# ADuCM410 register map
Vendor: Analog Devices; Series: ADuCM410; File version: 1p0
CPU: CM33 r0p1, little endian, MPU, FPU, 3 interrupt priority bits
Registers are 32-bit, read-write, reset 0x0 unless marked. A register's access mark holds for its fields unless they carry their own. Offsets are from the block's base; [hi:lo] are bit positions; {n}, {i} and the like mark numbered series.

## UART0
Base 0x40020000
Same registers: UART1 0x40020400
0x00 RX — Receive/transfer Buffer Register
  [7:0] RBR ro — Receive Buffer Register
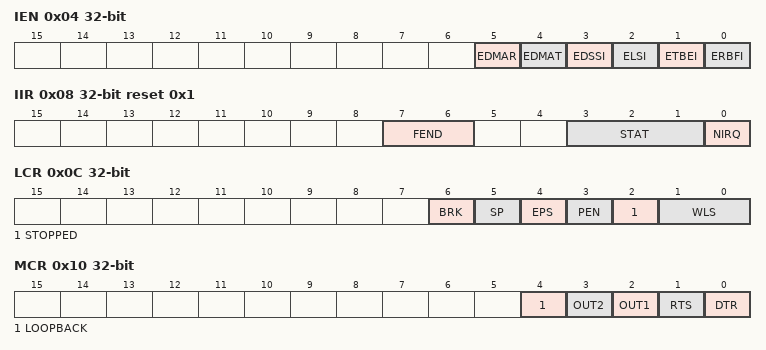
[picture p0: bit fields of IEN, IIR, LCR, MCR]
0x04 IEN — Interrupt Enable
  [5] EDMAR — DMA Requests in Receive Mode
    0=DIS (DMA Requests Disabled); 1=EN (DMA Requests Enabled)
  [4] EDMAT — DMA Requests in Transmit Mode
    0=DIS (DMA Requests are Disabled); 1=EN (DMA Requests are Enabled)
  [3] EDSSI — Modem Status Interrupt
    0=DIS (Interrupt Disabled); 1=EN (Interrupt Enabled)
  [2] ELSI — Rx Status Interrupt
    0=DIS (Interrupt Disabled); 1=EN (Interrupt Enabled)
  [1] ETBEI — Transmit Buffer Empty Interrupt
    0=DIS (Interrupt Disabled); 1=EN (Interrupt Enabled)
  [0] ERBFI — Receive Buffer Full Interrupt
    0=DIS (Interrupt Disabled); 1=EN (Interrupt Enabled)
0x08 IIR reset 0x1 — Interrupt ID
  [7:6] FEND ro — FIFO Enabled
    0=DIS (FIFO Not Enabled, 16450 Mode); 3=EN (FIFO Enabled, 16550 Mode)
  [3:1] STAT ro — Interrupt Status
    0=MODEMINT (Modem Status Interrupt (Read MSR Register to Clear)); 1=TXEMPTYINT (Transmit Buffer Empty Interrupt (Write to Tx Register or Read IIR Register to Clear)); 2=RXFULLINT (Receive Buffer Full Interrupt (Read Rx Register to Clear)); 3=RXLINEINT (Receive Line Status Interrupt (Read LSR Register to Clear)); 6=RXTIMEOUTINT (Receive FIFO Time-out Interrupt (Read Rx Register to Clear))
  [0] NIRQ ro — Interrupt Flag
0x0C LCR — Line Control
  [6] BRK range 0x00000000..0x00000001 — Set Break
  [5] SP — Stick Parity
    0=STICK (Parity Will Not Be Forced Based on Parity Select and Parity Enable Bits.); 1=EPSPEN (Parity Forced Based on Parity Select and Parity Enable Bits.)
  [4] EPS — Parity Select
    0=ODD (Odd Parity Will Be Transmitted and Checked.); 1=EVEN (Even Parity Will Be Transmitted and Checked.)
  [3] PEN — Parity Enable
    0=DIS (Parity Will Not Be Transmitted or Checked.); 1=EN (Parity Will Be Transmitted and Checked.)
  [2] STOPPED — Stop Bit
    0=ONTBIT (Send 1 Stop Bit Regardless of the Word Length Select Bit); 1=MULTIBIT (Send a Number of Stop Bits Based on the Word Length as Follows: WLS = 00, 1.5 Stop Bits Transmitted (5-bit Word Length) WLS = 01 or 10 or 11, 2 Stop Bits Transmitted (6 or 7 or 8-bit Word Length))
  [1:0] WLS — Word Length Select
    {v}=BITS{v+5} ({v+5} Bits) (v=0..3)
0x10 MCR — Modem Control
  [4] LOOPBACK — Loop Back Mode
    0=DIS (Normal Operation - Loopback Disabled); 1=EN (Loopback Enabled)
  [3] OUT2 — Output 2
    0=FORCE1 (Force NOUT2 to a Logic 1); 1=FORCE0 (Force NOUT2 to a Logic 0)
  [2] OUT1 — Output 1
    0=FORCE1 (Force NOUT1 to a Logic 1); 1=FORCE0 (Force NOUT1 to a Logic 0)
  [1] RTS — Request to Send
    0=FORCE1 (Force NRTS to a Logic 1); 1=FORCE0 (Force NRTS to a Logic 0)
  [0] DTR — Data Terminal Ready
    0=FORCE1 (Force NDTR to a Logic 1); 1=FORCE0 (Force NDTR to a Logic 0)
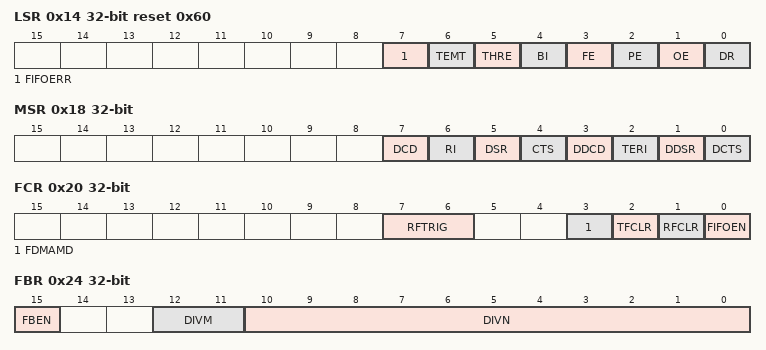
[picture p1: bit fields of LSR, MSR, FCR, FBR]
0x14 LSR reset 0x60 — Line Status
  [7] FIFOERR ro — FIFO Error
  [6] TEMT ro — Transmit and Shift Register Empty Status
    0=NOTEMPTY (Tx Register Has Been Written to and Contains Data to Be Transmitted. Care Should Be Taken Not to Overwrite Its Value.); 1=EMPTY (Tx Register and the Transmit Shift Register are Empty and It is Safe to Write New Data to the Tx Register. Data Has Been Transmitted.)
  [5] THRE ro — Transmit Register Empty
    0=NOTEMPTY (Tx Register Has Been Written to and Contains Data to Be Transmitted. Care Should Be Taken Not to Overwrite Its Value.); 1=EMPTY (Tx Register is Empty and It is Safe to Write New Data to Tx Register the Previous Data May Not Have Been Transmitted Yet and Can Still Be Present in the Shift Register.)
  [4] BI ro — Break Indicator
  [3] FE ro — Framing Error
    0=OKAY (No Invalid Stop Bit Was Detected.); 1=INVALIDSTOP (An Invalid Stop Bit Was Detected on a Received Word.)
  [2] PE ro — Parity Error
    0=NOERR (No Parity Error Was Detected.); 1=ERRORS (A Parity Error Occurred on a Received Word.)
  [1] OE ro — Overrun Error
    0=OKAY (Receive Data Has Not Been Overwritten.); 1=OVERWRITTEN (Receive Data Was Overwritten by New Data Before Rx Register Was Read.)
  [0] DR ro — Data Ready
    0=NOTREADY (Rx Register Does Not Contain New Receive Data.); 1=READY (Rx Register Contains Receive Data That Should Be Read.)
0x18 MSR — Modem Status
  [7] DCD ro — Data Carrier Detect
    0=HIGH (NDCD is Currently Logic High.); 1=LOW (NDCD is Currently Logic Low.)
  [6] RI ro — Ring Indicator
    0=HIGH (NRI is Currently Logic High.); 1=LOW (NRI is Currently Logic Low.)
  [5] DSR ro — Data Set Ready
    0=HIGH (NDSR is Currently Logic High); 1=LOW (NDSR is Currently Logic Low)
  [4] CTS ro — Clear to Send
    0=HIGH (NCTS is Currently Logic High); 1=LOW (NCTS is Currently Logic Low)
  [3] DDCD ro — Delta DCD
    0=NOCHANGE (Data Carrier Detect Bit Has Not Changed State Since MSR Register Was Last Read); 1=CHANGED (Data Carrier Detect Bit Changed State Since MSR Register Last Read)
  [2] TERI ro — Trailing Edge RI
    0=NOTCHANGED (Ring Indicator Bit Has Not Changed from 0 to 1 Since MSR Register Last Read); 1=CHANGED (Ring Indicator Bit Changed from 0 to 1 Since MSR Register Last Read)
  [1] DDSR ro — Delta DSR
    0=NOCHANGE (Data Set Ready Bit Has Not Changed State Since MSR Register Was Last Read); 1=CHANGED (Data Set Ready Bit Changed State Since MSR Register Last Read)
  [0] DCTS ro — Delta CTS
    0=NOCHANGE (Clear to Send Bit Has Not Changed State Since MSR Register Was Last Read); 1=CHANGED (Clear to Send Bit Changed State Since MSR Register Last Read)
0x1C SCR — Scratch Buffer
  [7:0] SCR range 0x00000000..0x000000FF — Scratch
0x20 FCR — FIFO Control
  [7:6] RFTRIG — RX FIFO Trig Level
    0=BYTE1 (1 Byte to Trig RX Interrupt); 1=BYTE4 (4 Byte to Trig RX Interrupt); 2=BYTE8 (8 Byte to Trig RX Interrupt); 3=BYTE14 (14 Byte to Trig RX Interrupt)
  [3] FDMAMD — FIFO DMA Mode
    0=MODE0 (In DMA Mode 0, RX DMA Request Will Be Asserted Whenever There's Data in RBR or RX FIFO and De-assert Whenever RBR or RX FIFO is Empty; TX DMA Request Will Be Asserted Whenever THR or TX FIFO is Empty and De-assert Whenever Data Written To.); 1=MODE1 (In DMA Mode 1, RX DMA Request Will Be Asserted Whenever RX FIFO Trig Level or Time Out Reached and De-assert Thereafter When RX FIFO is Empty; TX DMA Request Will Be Asserted Whenever TX FIFO is Empty and De-assert Thereafter When TX FIFO is Completely Filled up Full.)
  [2] TFCLR wo range 0x00000000..0x00000001 — Clear TX FIFO
  [1] RFCLR wo range 0x00000000..0x00000001 — Clear RX FIFO
  [0] FIFOEN range 0x00000000..0x00000001 — FIFO Enable as to Work in 16550 Mode
0x24 FBR — Fractional Baud Rate
  [15] FBEN range 0x00000000..0x00000001 — Fractional Baud Rate Generator Enable
  [12:11] DIVM range 0x00000000..0x00000003 — Fractional Baud Rate M Divide Bits 1 to 3
  [10:0] DIVN range 0x00000000..0x000007FF — Fractional Baud Rate N Divide Bits 0 to 2047
0x28 DIV — Baudrate Divider
  [15:0] DIV range 0x00000000..0x0000FFFF — Baud Rate Divider
0x2C LCR2 reset 0x2 — Second Line Control
  [1:0] OSR — Over Sample Rate
    0=Over Sample by 4; 1=Over Sample by 8; 2=Over Sample by 16; 3=Over Sample by 32
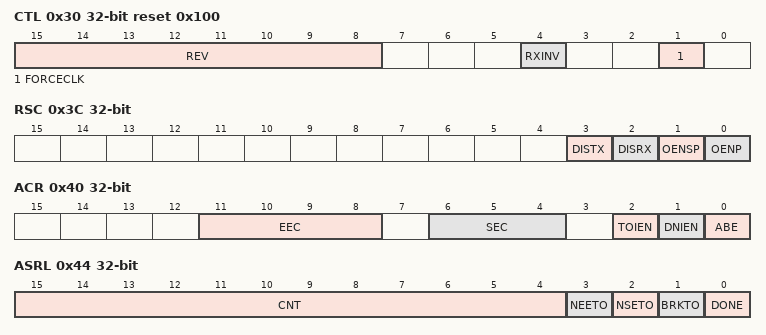
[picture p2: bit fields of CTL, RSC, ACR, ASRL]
0x30 CTL reset 0x100 — UART Control Register
  [15:8] REV ro — UART Revision ID
  [4] RXINV — Invert Receiver Line
    0=EN000 (Don't Invert Receiver Line (idling High)); 1=EN001 (Invert Receiver Line (idling Low))
  [1] FORCECLK — Force UCLK on
    0=GATEUCLK (UCLK Automatically Gated); 1=UCLKEN (UCLK Always Working)
0x34 RFC — RX FIFO Byte Count
  [4:0] RFC ro — Current RX FIFO Data Bytes
0x38 TFC — TX FIFO Byte Count
  [4:0] TFC ro — Current TX FIFO Data Bytes
0x3C RSC — RS485 Half-duplex Control
  [3] DISTX range 0x00000000..0x00000001 — Hold off TX When Receiving
  [2] DISRX range 0x00000000..0x00000001 — Disable RX When Transmitting
  [1] OENSP — SOUT_EN De-assert Before Full Stop Bit(s)
    0=FULLBIT (SOUT_EN De-assert Same Time as Full Stop Bit(s)); 1=HALFBIT (SOUT_EN De-assert Half-bit Earlier Than Full Stop Bit(s))
  [0] OENP — SOUT_EN Polarity
    0=HIGHACTIVE; 1=LOWACTIVE
0x40 ACR — Auto Baud Control
  [11:8] EEC — Ending Edge Count
    0=FIRST (First Edge); 1=SECOND (Second Edge); 2=THIRD (Third Edge); 3=FOURTH (Fourth Edge); 4=FIFTH (Fifth Edge); 5=SIXTH (Sixth Edge); 6=SEVENTH (Seventh Edge); 7=EIGHTH (Eighth Edge); 8=NINTH (Ninth Edge)
  [6:4] SEC — Starting Edge Count
    0=FIRST (First Edge (always the Falling Edge of START Bit)); 1=SECOND (Second Edge); 2=THIRD (Third Edge); 3=FOURTH (Fourth Edge); 4=FIFTH (Fifth Edge); 5=SIXTH (Sixth Edge); 6=SEVENTH (Seventh Edge); 7=EIGHTH (Eighth Edge)
  [2] TOIEN range 0x00000000..0x00000001 — Enable Time-out Interrupt
  [1] DNIEN range 0x00000000..0x00000001 — Enable Done Interrupt
  [0] ABE range 0x00000000..0x00000001 — Auto Baud Enable
0x44 ASRL — Auto Baud Status (Low)
  [15:4] CNT ro — Auto Baud Counter Value
  [3] NEETO ro — Timed Out Due to No Valid Ending Edge Found
  [2] NSETO ro — Timed Out Due to No Valid Start Edge Found
  [1] BRKTO ro — Timed Out Due to Long Time Break Condition
  [0] DONE ro — Auto Baud Done Successfully
0x48 ASRH — Auto Baud Status (High)
  [7:0] CNT ro — Auto Baud Counter Value
